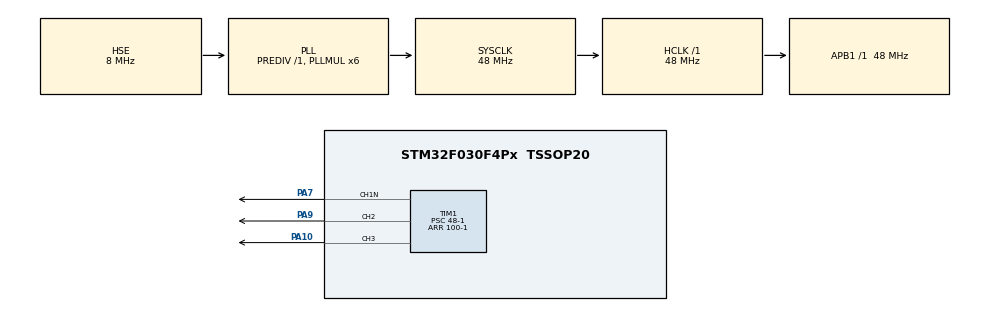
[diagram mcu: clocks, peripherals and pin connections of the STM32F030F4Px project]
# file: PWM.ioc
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Mcu.Family=STM32F0
Mcu.Name=STM32F030F4Px
Mcu.Package=TSSOP20
PA10.GPIO_PuPd=GPIO_PULLDOWN
PA10.Signal=S_TIM1_CH3
PA13.Mode=Serial_Wire
PA13.Signal=SYS_SWDIO
PA14.Mode=Serial_Wire
PA14.Signal=SYS_SWCLK
PA7.GPIO_PuPd=GPIO_PULLDOWN
PA7.Mode=PWM Generation1 CH1N
PA7.Signal=TIM1_CH1N
PA9.GPIO_PuPd=GPIO_PULLDOWN
PA9.Signal=S_TIM1_CH2
PF0-OSC_IN.Mode=HSE-External-Oscillator
PF0-OSC_IN.Signal=RCC_OSC_IN
PF1-OSC_OUT.Mode=HSE-External-Oscillator
PF1-OSC_OUT.Signal=RCC_OSC_OUT
ProjectManager.HeapSize=0x200
ProjectManager.StackSize=0x400
ProjectManager.TargetToolchain=STM32CubeIDE
RCC.AHBFreq_Value=48000000
RCC.APB1Freq_Value=48000000
RCC.APB1TimFreq_Value=48000000
RCC.HCLKFreq_Value=48000000
RCC.PLLMUL=RCC_PLL_MUL6
RCC.PLLSourceVirtual=RCC_PLLSOURCE_HSE
RCC.SYSCLKFreq_VALUE=48000000
RCC.SYSCLKSource=RCC_SYSCLKSOURCE_PLLCLK
SH.S_TIM1_CH2.0=TIM1_CH2,PWM Generation2 CH2
SH.S_TIM1_CH3.0=TIM1_CH3,PWM Generation3 CH3
TIM1.Channel-PWM\ Generation1\ CH1N=TIM_CHANNEL_1
TIM1.Channel-PWM\ Generation2\ CH2=TIM_CHANNEL_2
TIM1.Channel-PWM\ Generation3\ CH3=TIM_CHANNEL_3
TIM1.Period=100-1
TIM1.Prescaler=48-1
VP_TIM1_VS_ClockSourceINT.Mode=Internal
board=custom

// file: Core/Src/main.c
/* USER CODE BEGIN Header */
/**
 ******************************************************************************
 * @file           : main.c
 * @brief          : Main program body
 ******************************************************************************
 * @attention
 *
 * <h2><center>&copy; Copyright (c) 2022 STMicroelectronics.
 * All rights reserved.</center></h2>
 *
 * This software component is licensed by ST under BSD 3-Clause license,
 * the "License"; You may not use this file except in compliance with the
 * License. You may obtain a copy of the License at:
 *                        opensource.org/licenses/BSD-3-Clause
 *
 ******************************************************************************
 */
/* USER CODE END Header */

#include "main.h"
#include "tim.h"
#include "gpio.h"

void SystemClock_Config(void);

int main(void)
{

  /* MCU Configuration--------------------------------------------------------*/

  /* Reset of all peripherals, Initializes the Flash interface and the Systick. */
  HAL_Init();

  /* Configure the system clock */
  SystemClock_Config();

  /* Initialize all configured peripherals */
  MX_GPIO_Init();
  MX_TIM1_Init();
  /* USER CODE BEGIN 2 */
	TIM1->CCR1 = 50;
	TIM1->CCR2 = 50;
	TIM1->CCR3 = 50;
	HAL_TIM_PWM_Start(&htim1, TIM_CHANNEL_1);
	HAL_TIM_PWM_Start(&htim1, TIM_CHANNEL_2);
	HAL_TIM_PWM_Start(&htim1, TIM_CHANNEL_3);
	HAL_Delay(1000);
	HAL_TIM_PWM_Stop(&htim1, TIM_CHANNEL_1);
	HAL_TIM_PWM_Stop(&htim1, TIM_CHANNEL_2);
	HAL_TIM_PWM_Stop(&htim1, TIM_CHANNEL_3);
  /* USER CODE END 2 */

  /* Infinite loop */
	while (1)
	{

	}
}

void SystemClock_Config(void)
{
  RCC_OscInitTypeDef RCC_OscInitStruct = {0};
  RCC_ClkInitTypeDef RCC_ClkInitStruct = {0};

  /** Initializes the CPU, AHB and APB busses clocks
  */
  RCC_OscInitStruct.OscillatorType = RCC_OSCILLATORTYPE_HSE;
  RCC_OscInitStruct.HSEState = RCC_HSE_ON;
  RCC_OscInitStruct.PLL.PLLState = RCC_PLL_ON;
  RCC_OscInitStruct.PLL.PLLSource = RCC_PLLSOURCE_HSE;
  RCC_OscInitStruct.PLL.PLLMUL = RCC_PLL_MUL6;
  RCC_OscInitStruct.PLL.PREDIV = RCC_PREDIV_DIV1;
  if (HAL_RCC_OscConfig(&RCC_OscInitStruct) != HAL_OK)
  {
    Error_Handler();
  }
  /** Initializes the CPU, AHB and APB busses clocks
  */
  RCC_ClkInitStruct.ClockType = RCC_CLOCKTYPE_HCLK|RCC_CLOCKTYPE_SYSCLK
                              |RCC_CLOCKTYPE_PCLK1;
  RCC_ClkInitStruct.SYSCLKSource = RCC_SYSCLKSOURCE_PLLCLK;
  RCC_ClkInitStruct.AHBCLKDivider = RCC_SYSCLK_DIV1;
  RCC_ClkInitStruct.APB1CLKDivider = RCC_HCLK_DIV1;

  if (HAL_RCC_ClockConfig(&RCC_ClkInitStruct, FLASH_LATENCY_1) != HAL_OK)
  {
    Error_Handler();
  }
}

void Error_Handler(void)
{
}

/************************ (C) COPYRIGHT STMicroelectronics *****END OF FILE****/
